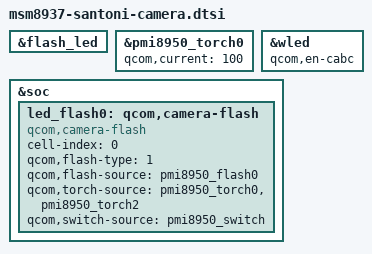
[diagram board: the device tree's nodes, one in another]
#include "msm8937-camera-sensor-santoni.dtsi"

&flash_led {
	/delete-node/ qcom,flash_1;
	/delete-node/ qcom,torch_1;
};

&pmi8950_torch0 {
	qcom,current = <100>;
};

&wled {
	qcom,en-cabc;
};

&soc {
	led_flash0: qcom,camera-flash {
		cell-index = <0>;
		compatible = "qcom,camera-flash";
		qcom,flash-type = <1>;
		qcom,flash-source = <&pmi8950_flash0>;
		qcom,torch-source = <&pmi8950_torch0 &pmi8950_torch2>;
		qcom,switch-source = <&pmi8950_switch>;
	};
};
